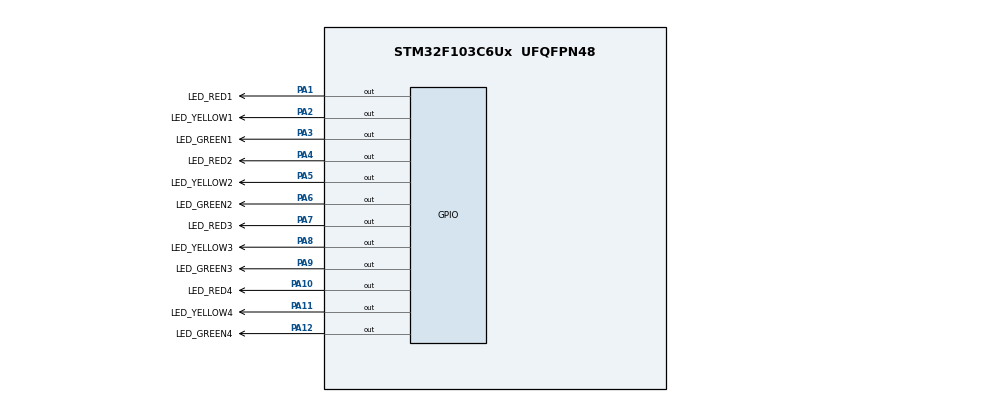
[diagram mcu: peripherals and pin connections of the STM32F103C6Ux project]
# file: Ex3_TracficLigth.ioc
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Mcu.Family=STM32F1
Mcu.Name=STM32F103C6Ux
Mcu.Package=UFQFPN48
NVIC.PriorityGroup=NVIC_PRIORITYGROUP_4
PA1.GPIO_Label=LED_RED1
PA1.Signal=GPIO_Output
PA10.GPIO_Label=LED_RED4
PA10.Signal=GPIO_Output
PA11.GPIO_Label=LED_YELLOW4
PA11.Signal=GPIO_Output
PA12.GPIO_Label=LED_GREEN4
PA12.Signal=GPIO_Output
PA2.GPIO_Label=LED_YELLOW1
PA2.Signal=GPIO_Output
PA3.GPIO_Label=LED_GREEN1
PA3.Signal=GPIO_Output
PA4.GPIO_Label=LED_RED2
PA4.Signal=GPIO_Output
PA5.GPIO_Label=LED_YELLOW2
PA5.Signal=GPIO_Output
PA6.GPIO_Label=LED_GREEN2
PA6.Signal=GPIO_Output
PA7.GPIO_Label=LED_RED3
PA7.Signal=GPIO_Output
PA8.GPIO_Label=LED_YELLOW3
PA8.Signal=GPIO_Output
PA9.GPIO_Label=LED_GREEN3
PA9.Signal=GPIO_Output
ProjectManager.HeapSize=0x200
ProjectManager.StackSize=0x400
ProjectManager.TargetToolchain=STM32CubeIDE
RCC.APB1Freq_Value=8000000
RCC.APB2Freq_Value=8000000
VP_SYS_VS_ND.Mode=No_Debug
board=custom

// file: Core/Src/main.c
/* USER CODE BEGIN Header */
/**
  ******************************************************************************
  * @file           : main.c
  * @brief          : Main program body
  ******************************************************************************
  * @attention
  *
  * <h2><center>&copy; Copyright (c) 2022 STMicroelectronics.
  * All rights reserved.</center></h2>
  *
  * This software component is licensed by ST under BSD 3-Clause license,
  * the "License"; You may not use this file except in compliance with the
  * License. You may obtain a copy of the License at:
  *                        opensource.org/licenses/BSD-3-Clause
  *
  ******************************************************************************
  */
/* USER CODE END Header */
#include "main.h"

void SystemClock_Config(void);
static void MX_GPIO_Init(void);

int main(void)
{

  /* MCU Configuration--------------------------------------------------------*/

  /* Reset of all peripherals, Initializes the Flash interface and the Systick. */
  HAL_Init();

  /* Configure the system clock */
  SystemClock_Config();

  /* Initialize all configured peripherals */
  MX_GPIO_Init();

  /* Infinite loop */
  /* USER CODE BEGIN WHILE */
  int time_red =5;
  int time_yellow =2;
  int time_green =3;
  int couter_time=0;
  int led_status =0;
  while (1)
  {
    /* USER CODE END WHILE */
	  if(led_status ==0){
	  // DEN DO KICH HOAT
	  	// DO 13 XANH 24
	  	  	HAL_GPIO_WritePin ( LED_RED1_GPIO_Port , LED_RED1_Pin ,  GPIO_PIN_RESET ) ;
	  		HAL_GPIO_WritePin ( LED_RED2_GPIO_Port , LED_RED2_Pin ,  GPIO_PIN_SET ) ;
	  		HAL_GPIO_WritePin ( LED_RED3_GPIO_Port , LED_RED3_Pin ,  GPIO_PIN_RESET ) ;
	  		HAL_GPIO_WritePin ( LED_RED4_GPIO_Port , LED_RED4_Pin ,  GPIO_PIN_SET ) ;

	  		HAL_GPIO_WritePin ( LED_YELLOW1_GPIO_Port , LED_YELLOW1_Pin ,  GPIO_PIN_SET ) ;
	  		HAL_GPIO_WritePin ( LED_YELLOW2_GPIO_Port , LED_YELLOW2_Pin ,  GPIO_PIN_SET ) ;
	  		HAL_GPIO_WritePin ( LED_YELLOW3_GPIO_Port , LED_YELLOW3_Pin ,  GPIO_PIN_SET ) ;
	  		HAL_GPIO_WritePin ( LED_YELLOW4_GPIO_Port , LED_YELLOW4_Pin ,  GPIO_PIN_SET ) ;

	  		HAL_GPIO_WritePin ( LED_GREEN1_GPIO_Port , LED_GREEN1_Pin ,  GPIO_PIN_SET ) ;
	  		HAL_GPIO_WritePin ( LED_GREEN2_GPIO_Port , LED_GREEN2_Pin ,  GPIO_PIN_RESET ) ;
	  		HAL_GPIO_WritePin ( LED_GREEN3_GPIO_Port , LED_GREEN3_Pin ,  GPIO_PIN_SET ) ;
	  		HAL_GPIO_WritePin ( LED_GREEN4_GPIO_Port , LED_GREEN4_Pin ,  GPIO_PIN_RESET ) ;
	  		if(couter_time>time_red-time_yellow){
	  			led_status = 1;
	  			couter_time =0;
	  		}else{
	  			couter_time =couter_time+1;
	  			led_status =0;
		  		HAL_Delay(1000);

	  		}
	  }
	  if(led_status ==1){
		  //// DO 13 VANG 24

		  		HAL_GPIO_WritePin ( LED_RED1_GPIO_Port , LED_RED1_Pin ,  GPIO_PIN_RESET ) ;
		  		HAL_GPIO_WritePin ( LED_RED2_GPIO_Port , LED_RED2_Pin ,  GPIO_PIN_SET ) ;
		  		HAL_GPIO_WritePin ( LED_RED3_GPIO_Port , LED_RED3_Pin ,  GPIO_PIN_RESET ) ;
		  		HAL_GPIO_WritePin ( LED_RED4_GPIO_Port , LED_RED4_Pin ,  GPIO_PIN_SET ) ;

		  		HAL_GPIO_WritePin ( LED_YELLOW1_GPIO_Port , LED_YELLOW1_Pin ,  GPIO_PIN_SET ) ;
		  		HAL_GPIO_WritePin ( LED_YELLOW2_GPIO_Port , LED_YELLOW2_Pin ,  GPIO_PIN_RESET ) ;
		  		HAL_GPIO_WritePin ( LED_YELLOW3_GPIO_Port , LED_YELLOW3_Pin ,  GPIO_PIN_SET ) ;
		  		HAL_GPIO_WritePin ( LED_YELLOW4_GPIO_Port , LED_YELLOW4_Pin ,  GPIO_PIN_RESET ) ;

		  		HAL_GPIO_WritePin ( LED_GREEN1_GPIO_Port , LED_GREEN1_Pin ,  GPIO_PIN_SET ) ;
		  		HAL_GPIO_WritePin ( LED_GREEN2_GPIO_Port , LED_GREEN2_Pin ,  GPIO_PIN_SET ) ;
		  		HAL_GPIO_WritePin ( LED_GREEN3_GPIO_Port , LED_GREEN3_Pin ,  GPIO_PIN_SET ) ;
		  		HAL_GPIO_WritePin ( LED_GREEN4_GPIO_Port , LED_GREEN4_Pin ,  GPIO_PIN_SET ) ;
		  		if(couter_time>time_red-time_green){
		  			  			led_status = 2;
		  			  			couter_time =0;
		  		}else{
		  			  	couter_time =couter_time+1;
		  			  	led_status =1;
  			  			HAL_Delay(1000);
		  		}
	  }
	  if(led_status ==2){
		  // DEN XANH KICH HOAT

		  	// DO 24 XANH 13
		  		HAL_GPIO_WritePin ( LED_RED1_GPIO_Port , LED_RED1_Pin ,  GPIO_PIN_SET ) ;
		  		HAL_GPIO_WritePin ( LED_RED2_GPIO_Port , LED_RED2_Pin ,  GPIO_PIN_RESET ) ;
		  		HAL_GPIO_WritePin ( LED_RED3_GPIO_Port , LED_RED3_Pin ,  GPIO_PIN_SET ) ;
		  		HAL_GPIO_WritePin ( LED_RED4_GPIO_Port , LED_RED4_Pin ,  GPIO_PIN_RESET ) ;

		  		HAL_GPIO_WritePin ( LED_YELLOW1_GPIO_Port , LED_YELLOW1_Pin ,  GPIO_PIN_SET ) ;
		  		HAL_GPIO_WritePin ( LED_YELLOW2_GPIO_Port , LED_YELLOW2_Pin ,  GPIO_PIN_SET ) ;
		  		HAL_GPIO_WritePin ( LED_YELLOW3_GPIO_Port , LED_YELLOW3_Pin ,  GPIO_PIN_SET ) ;
		  		HAL_GPIO_WritePin ( LED_YELLOW4_GPIO_Port , LED_YELLOW4_Pin ,  GPIO_PIN_SET ) ;

		  		HAL_GPIO_WritePin ( LED_GREEN1_GPIO_Port , LED_GREEN1_Pin ,  GPIO_PIN_RESET ) ;
		  		HAL_GPIO_WritePin ( LED_GREEN2_GPIO_Port , LED_GREEN2_Pin ,  GPIO_PIN_SET ) ;
		  		HAL_GPIO_WritePin ( LED_GREEN3_GPIO_Port , LED_GREEN3_Pin ,  GPIO_PIN_RESET ) ;
		  		HAL_GPIO_WritePin ( LED_GREEN4_GPIO_Port , LED_GREEN4_Pin ,  GPIO_PIN_SET ) ;
		  		if(couter_time>time_red-time_yellow){
		  			  			led_status = 3;
		  			  			couter_time =0;
		  			  		}else{
		  			  			couter_time =couter_time+1;
		  			  			led_status =2;
		  			  			HAL_Delay(1000);
		  			  		}
	  }
	  if(led_status == 3){

		  // DEN XANH KICH HOAT

		  	//// DO 24 VANG 13

		  		HAL_GPIO_WritePin ( LED_RED1_GPIO_Port , LED_RED1_Pin ,  GPIO_PIN_SET ) ;
		  		HAL_GPIO_WritePin ( LED_RED2_GPIO_Port , LED_RED2_Pin ,  GPIO_PIN_RESET ) ;
		  		HAL_GPIO_WritePin ( LED_RED3_GPIO_Port , LED_RED3_Pin ,  GPIO_PIN_SET ) ;
		  		HAL_GPIO_WritePin ( LED_RED4_GPIO_Port , LED_RED4_Pin ,  GPIO_PIN_RESET ) ;

		  		HAL_GPIO_WritePin ( LED_YELLOW1_GPIO_Port , LED_YELLOW1_Pin ,  GPIO_PIN_RESET ) ;
		  		HAL_GPIO_WritePin ( LED_YELLOW2_GPIO_Port , LED_YELLOW2_Pin ,  GPIO_PIN_SET ) ;
		  		HAL_GPIO_WritePin ( LED_YELLOW3_GPIO_Port , LED_YELLOW3_Pin ,  GPIO_PIN_RESET ) ;
		  		HAL_GPIO_WritePin ( LED_YELLOW4_GPIO_Port , LED_YELLOW4_Pin ,  GPIO_PIN_SET ) ;

		  		HAL_GPIO_WritePin ( LED_GREEN1_GPIO_Port , LED_GREEN1_Pin ,  GPIO_PIN_SET ) ;
		  		HAL_GPIO_WritePin ( LED_GREEN2_GPIO_Port , LED_GREEN2_Pin ,  GPIO_PIN_SET ) ;
		  		HAL_GPIO_WritePin ( LED_GREEN3_GPIO_Port , LED_GREEN3_Pin ,  GPIO_PIN_SET ) ;
		  		HAL_GPIO_WritePin ( LED_GREEN4_GPIO_Port , LED_GREEN4_Pin ,  GPIO_PIN_SET ) ;
		  		if(couter_time>time_red-time_green){
		  				  			  			led_status = 0;
		  				  			  			couter_time =0;
		  				  		}else{
		  				  			  	couter_time =couter_time+1;
		  				  			  	led_status =3;
		  		  			  			HAL_Delay(1000);
		  				  		}

	  }
  }
}

void SystemClock_Config(void)
{
  RCC_OscInitTypeDef RCC_OscInitStruct = {0};
  RCC_ClkInitTypeDef RCC_ClkInitStruct = {0};

  /** Initializes the RCC Oscillators according to the specified parameters
  * in the RCC_OscInitTypeDef structure.
  */
  RCC_OscInitStruct.OscillatorType = RCC_OSCILLATORTYPE_HSI;
  RCC_OscInitStruct.HSIState = RCC_HSI_ON;
  RCC_OscInitStruct.HSICalibrationValue = RCC_HSICALIBRATION_DEFAULT;
  RCC_OscInitStruct.PLL.PLLState = RCC_PLL_NONE;
  if (HAL_RCC_OscConfig(&RCC_OscInitStruct) != HAL_OK)
  {
    Error_Handler();
  }
  /** Initializes the CPU, AHB and APB buses clocks
  */
  RCC_ClkInitStruct.ClockType = RCC_CLOCKTYPE_HCLK|RCC_CLOCKTYPE_SYSCLK
                              |RCC_CLOCKTYPE_PCLK1|RCC_CLOCKTYPE_PCLK2;
  RCC_ClkInitStruct.SYSCLKSource = RCC_SYSCLKSOURCE_HSI;
  RCC_ClkInitStruct.AHBCLKDivider = RCC_SYSCLK_DIV1;
  RCC_ClkInitStruct.APB1CLKDivider = RCC_HCLK_DIV1;
  RCC_ClkInitStruct.APB2CLKDivider = RCC_HCLK_DIV1;

  if (HAL_RCC_ClockConfig(&RCC_ClkInitStruct, FLASH_LATENCY_0) != HAL_OK)
  {
    Error_Handler();
  }
}

static void MX_GPIO_Init(void)
{
  GPIO_InitTypeDef GPIO_InitStruct = {0};

  /* GPIO Ports Clock Enable */
  __HAL_RCC_GPIOA_CLK_ENABLE();

  /*Configure GPIO pin Output Level */
  HAL_GPIO_WritePin(GPIOA, LED_RED1_Pin|LED_YELLOW1_Pin|LED_GREEN1_Pin|LED_RED2_Pin
                          |LED_YELLOW2_Pin|LED_GREEN2_Pin|LED_RED3_Pin|LED_YELLOW3_Pin
                          |LED_GREEN3_Pin|LED_RED4_Pin|LED_YELLOW4_Pin|LED_GREEN4_Pin, GPIO_PIN_RESET);

  /*Configure GPIO pins : LED_RED1_Pin LED_YELLOW1_Pin LED_GREEN1_Pin LED_RED2_Pin
                           LED_YELLOW2_Pin LED_GREEN2_Pin LED_RED3_Pin LED_YELLOW3_Pin
                           LED_GREEN3_Pin LED_RED4_Pin LED_YELLOW4_Pin LED_GREEN4_Pin */
  GPIO_InitStruct.Pin = LED_RED1_Pin|LED_YELLOW1_Pin|LED_GREEN1_Pin|LED_RED2_Pin
                          |LED_YELLOW2_Pin|LED_GREEN2_Pin|LED_RED3_Pin|LED_YELLOW3_Pin
                          |LED_GREEN3_Pin|LED_RED4_Pin|LED_YELLOW4_Pin|LED_GREEN4_Pin;
  GPIO_InitStruct.Mode = GPIO_MODE_OUTPUT_PP;
  GPIO_InitStruct.Pull = GPIO_NOPULL;
  GPIO_InitStruct.Speed = GPIO_SPEED_FREQ_LOW;
  HAL_GPIO_Init(GPIOA, &GPIO_InitStruct);

}

void Error_Handler(void)
{
  __disable_irq();
  while (1)
  {
  }
}

/************************ (C) COPYRIGHT STMicroelectronics *****END OF FILE****/
